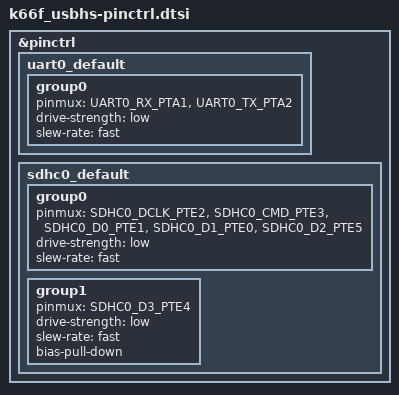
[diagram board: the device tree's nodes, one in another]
#include <nxp/kinetis/MK66FN2M0VMD18-pinctrl.h>

&pinctrl {
    uart0_default: uart0_default {
        group0 {
            pinmux = <UART0_RX_PTA1>,
                     <UART0_TX_PTA2>;
            drive-strength = "low";
            slew-rate = "fast";
        };
    };

    sdhc0_default: sdhc0_default {
        group0 {
            pinmux = <SDHC0_DCLK_PTE2>,
                     <SDHC0_CMD_PTE3>,
                     <SDHC0_D0_PTE1>,
                     <SDHC0_D1_PTE0>,
                     <SDHC0_D2_PTE5>;
            drive-strength = "low";
            slew-rate = "fast";
        };
        group1 {
            pinmux = <SDHC0_D3_PTE4>;
            drive-strength = "low";
            slew-rate = "fast";
            bias-pull-down; // needed for DAT3 detection
        };
    };
};
